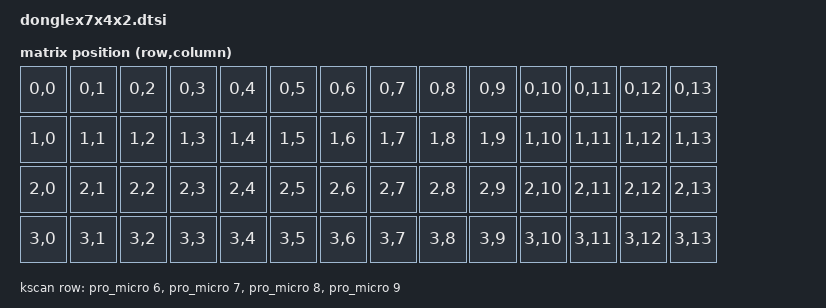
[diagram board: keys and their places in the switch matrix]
// This file was generated from a template. Edit it to match your keyboard.
// See https://zmk.dev/docs/development/hardware-integration/new-shield for more
// instructions.

#include <dt-bindings/zmk/matrix_transform.h>

#include "donglex7x4x2-layouts.dtsi"

/ {
    chosen {
        zmk,physical-layout = &default_layout;
    };

    kscan: kscan {
        // If the hardware does not use a switch matrix, change this to the
        // appropriate driver and update the properties below to match.
        // See https://zmk.dev/docs/config/kscan for supported key scan drivers.
        compatible = "zmk,kscan-gpio-matrix";
        // Set this to "col2row" or "row2col" to match the hardware. If using
        // "row2col", change the col-gpios in the _left.overlay and _right.overlay
        // files to (GPIO_ACTIVE_HIGH | GPIO_PULL_DOWN) and the row-gpios here to
        // GPIO_ACTIVE_HIGH.
        diode-direction = "col2row";
        wakeup-source;

        // Replace these comments with the GPIO pins in the matrix.
        // See https://zmk.dev/docs/development/hardware-integration/new-shield#shield-overlays
        row-gpios
            = <&pro_micro 6 (GPIO_ACTIVE_HIGH | GPIO_PULL_DOWN)>
            , <&pro_micro 7 (GPIO_ACTIVE_HIGH | GPIO_PULL_DOWN)>
            , <&pro_micro 8 (GPIO_ACTIVE_HIGH | GPIO_PULL_DOWN)>
            , <&pro_micro 9 (GPIO_ACTIVE_HIGH | GPIO_PULL_DOWN)>
            ;
    };

    default_transform: default_transform {
        compatible = "zmk,matrix-transform";
        columns = <6>;
        rows = <3>;
        map = <
        //  --- LEFT SIDE (7 columns) ---              --- RIGHT SIDE (7 columns) ---
        //  L01     L02     L03     L04     L05     L06     L07         R01     R02     R03     R04     R05     R06     R07
            RC(0,0) RC(0,1) RC(0,2) RC(0,3) RC(0,4) RC(0,5) RC(0,6)     RC(0,7) RC(0,8) RC(0,9) RC(0,10) RC(0,11) RC(0,12) RC(0,13)
        //  L08     L09     L10     L11     L12     L13     L14         R08     R09     R10     R11     R12     R13     R14
            RC(1,0) RC(1,1) RC(1,2) RC(1,3) RC(1,4) RC(1,5) RC(1,6)     RC(1,7) RC(1,8) RC(1,9) RC(1,10) RC(1,11) RC(1,12) RC(1,13)
        //  L15     L16     L17     L18     L19     L20     L21         R15     R16     R17     R18     R19     R20     R21
            RC(2,0) RC(2,1) RC(2,2) RC(2,3) RC(2,4) RC(2,5) RC(2,6)     RC(2,7) RC(2,8) RC(2,9) RC(2,10) RC(2,11) RC(2,12) RC(2,13)
        //  L22     L23     L24     L25     L26     L27     L28         R22     R23     R24     R25     R26     R27     R28
            RC(3,0) RC(3,1) RC(3,2) RC(3,3) RC(3,4) RC(3,5) RC(3,6)     RC(3,7) RC(3,8) RC(3,9) RC(3,10) RC(3,11) RC(3,12) RC(3,13)
        >;
    };
};
